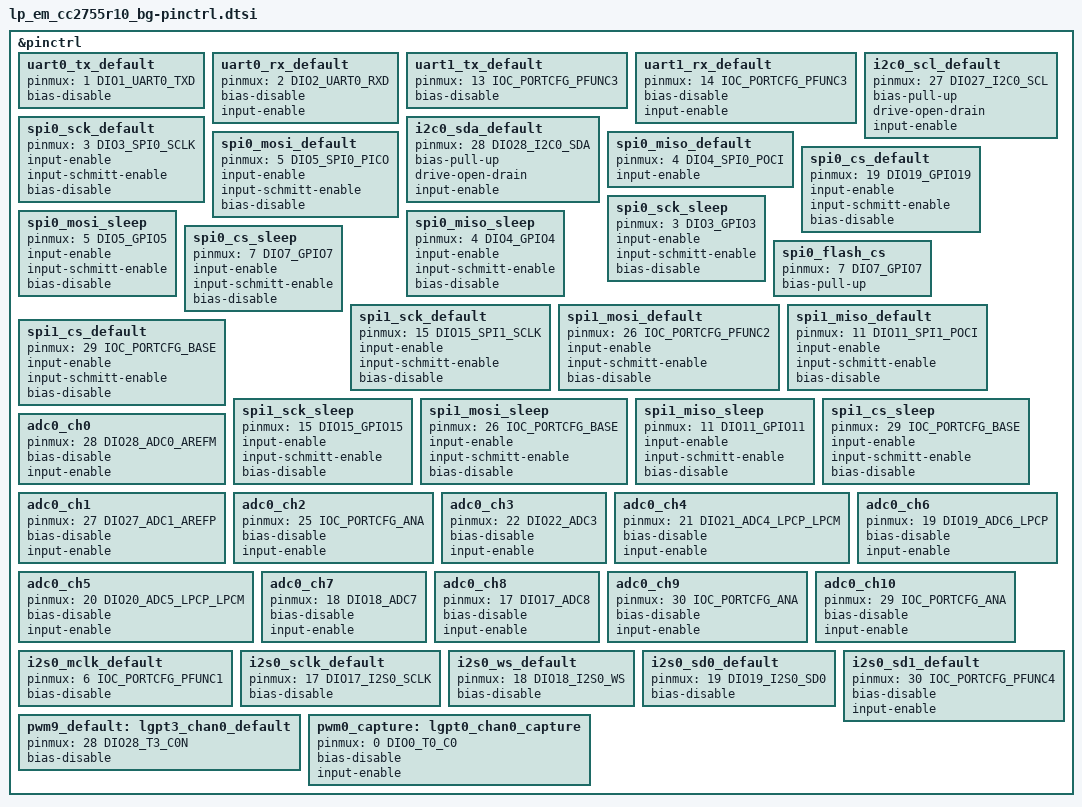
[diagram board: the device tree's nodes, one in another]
/*
 * Copyright (c) 2026 Texas Instruments Incorporated
 * Copyright (c) 2024 BayLibre, SAS
 *
 * SPDX-License-Identifier: Apache-2.0
 */

#include <zephyr/dt-bindings/pinctrl/cc27xx-pinctrl.h>

&pinctrl {
	/* UART0 */
	uart0_tx_default: uart0_tx_default {
		pinmux = <1 DIO1_UART0_TXD>;
		bias-disable;
	};

	uart0_rx_default: uart0_rx_default {
		pinmux = <2 DIO2_UART0_RXD>;
		bias-disable;
		input-enable;
	};

	/* UART1: DIO13 TXD, DIO14 RXD (mode 3) */
	uart1_tx_default: uart1_tx_default {
		pinmux = <13 IOC_PORTCFG_PFUNC3>;
		bias-disable;
	};

	uart1_rx_default: uart1_rx_default {
		pinmux = <14 IOC_PORTCFG_PFUNC3>;
		bias-disable;
		input-enable;
	};

	/* I2C0 */
	i2c0_scl_default: i2c0_scl_default {
		pinmux = <27 DIO27_I2C0_SCL>;
		bias-pull-up;
		drive-open-drain;
		input-enable;
	};

	i2c0_sda_default: i2c0_sda_default {
		pinmux = <28 DIO28_I2C0_SDA>;
		bias-pull-up;
		drive-open-drain;
		input-enable;
	};

	/* SPI0 */
	spi0_sck_default: spi0_sck_default {
		pinmux = <3 DIO3_SPI0_SCLK>;
		input-enable;
		input-schmitt-enable;
		bias-disable;
	};

	spi0_mosi_default: spi0_mosi_default {
		pinmux = <5 DIO5_SPI0_PICO>;
		input-enable;
		input-schmitt-enable;
		bias-disable;
	};

	spi0_miso_default: spi0_miso_default {
		pinmux = <4 DIO4_SPI0_POCI>;
		input-enable;
	};

	spi0_cs_default: spi0_cs_default {
		pinmux = <19 DIO19_GPIO19>;
		input-enable;
		input-schmitt-enable;
		bias-disable;
	};

	spi0_sck_sleep: spi0_sck_sleep {
		pinmux = <3 DIO3_GPIO3>;
		input-enable;
		input-schmitt-enable;
		bias-disable;
	};

	spi0_mosi_sleep: spi0_mosi_sleep {
		pinmux = <5 DIO5_GPIO5>;
		input-enable;
		input-schmitt-enable;
		bias-disable;
	};

	spi0_miso_sleep: spi0_miso_sleep {
		pinmux = <4 DIO4_GPIO4>;
		input-enable;
		input-schmitt-enable;
		bias-disable;
	};

	spi0_cs_sleep: spi0_cs_sleep {
		pinmux = <7 DIO7_GPIO7>;
		input-enable;
		input-schmitt-enable;
		bias-disable;
	};

	spi0_flash_cs: spi0_flash_cs {
		pinmux = <7 DIO7_GPIO7>;
		bias-pull-up;
	};

	/* SPI1: DIO15 SCLK, DIO26 PICO, DIO11 POCI, DIO29 CS (GPIO) */
	spi1_sck_default: spi1_sck_default {
		pinmux = <15 DIO15_SPI1_SCLK>;
		input-enable;
		input-schmitt-enable;
		bias-disable;
	};

	spi1_mosi_default: spi1_mosi_default {
		pinmux = <26 IOC_PORTCFG_PFUNC2>;
		input-enable;
		input-schmitt-enable;
		bias-disable;
	};

	spi1_miso_default: spi1_miso_default {
		pinmux = <11 DIO11_SPI1_POCI>;
		input-enable;
		input-schmitt-enable;
		bias-disable;
	};

	spi1_cs_default: spi1_cs_default {
		pinmux = <29 IOC_PORTCFG_BASE>;
		input-enable;
		input-schmitt-enable;
		bias-disable;
	};

	spi1_sck_sleep: spi1_sck_sleep {
		pinmux = <15 DIO15_GPIO15>;
		input-enable;
		input-schmitt-enable;
		bias-disable;
	};

	spi1_mosi_sleep: spi1_mosi_sleep {
		pinmux = <26 IOC_PORTCFG_BASE>;
		input-enable;
		input-schmitt-enable;
		bias-disable;
	};

	spi1_miso_sleep: spi1_miso_sleep {
		pinmux = <11 DIO11_GPIO11>;
		input-enable;
		input-schmitt-enable;
		bias-disable;
	};

	spi1_cs_sleep: spi1_cs_sleep {
		pinmux = <29 IOC_PORTCFG_BASE>;
		input-enable;
		input-schmitt-enable;
		bias-disable;
	};

	/* ADC channels.
	 *
	 * Some pins are shared with other options and must not be selected
	 * together: ch5 (DIO20) with Button 1, ch6/7/8 (DIO19/18/17) with I2S0,
	 * ch9 (DIO30) with I2S0 SD1, ch10 (DIO29) with the SPI1 CS, and ch0/ch1
	 * (DIO28/27) with I2C0.
	 */

	adc0_ch0: adc0_ch0 {
		pinmux = <28 DIO28_ADC0_AREFM>;
		bias-disable;
		input-enable;
	};

	adc0_ch1: adc0_ch1 {
		pinmux = <27 DIO27_ADC1_AREFP>;
		bias-disable;
		input-enable;
	};

	adc0_ch2: adc0_ch2 {
		pinmux = <25 IOC_PORTCFG_ANA>;
		bias-disable;
		input-enable;
	};

	adc0_ch3: adc0_ch3 {
		pinmux = <22 DIO22_ADC3>;
		bias-disable;
		input-enable;
	};

	adc0_ch4: adc0_ch4 {
		pinmux = <21 DIO21_ADC4_LPCP_LPCM>;
		bias-disable;
		input-enable;
	};

	adc0_ch5: adc0_ch5 {
		pinmux = <20 DIO20_ADC5_LPCP_LPCM>;
		bias-disable;
		input-enable;
	};

	adc0_ch6: adc0_ch6 {
		pinmux = <19 DIO19_ADC6_LPCP>;
		bias-disable;
		input-enable;
	};

	adc0_ch7: adc0_ch7 {
		pinmux = <18 DIO18_ADC7>;
		bias-disable;
		input-enable;
	};

	adc0_ch8: adc0_ch8 {
		pinmux = <17 DIO17_ADC8>;
		bias-disable;
		input-enable;
	};

	adc0_ch9: adc0_ch9 {
		pinmux = <30 IOC_PORTCFG_ANA>;
		bias-disable;
		input-enable;
	};

	adc0_ch10: adc0_ch10 {
		pinmux = <29 IOC_PORTCFG_ANA>;
		bias-disable;
		input-enable;
	};

	/* I2S0 shares DIO17/18/19 with ADC ch8/7/6 and DIO30 with ADC ch9.
	 * DIO6=MCLK, DIO17=SCLK, DIO18=WS, DIO19=SD0(TX), DIO30=SD1(RX)
	 */
	i2s0_mclk_default: i2s0_mclk_default {
		pinmux = <6 IOC_PORTCFG_PFUNC1>;
		bias-disable;
	};

	i2s0_sclk_default: i2s0_sclk_default {
		pinmux = <17 DIO17_I2S0_SCLK>;
		bias-disable;
	};

	i2s0_ws_default: i2s0_ws_default {
		pinmux = <18 DIO18_I2S0_WS>;
		bias-disable;
	};

	i2s0_sd0_default: i2s0_sd0_default {
		pinmux = <19 DIO19_I2S0_SD0>;
		bias-disable;
	};

	i2s0_sd1_default: i2s0_sd1_default {
		pinmux = <30 IOC_PORTCFG_PFUNC4>;
		bias-disable;
		input-enable;
	};

	/* LGPT3 ch0 output (DIO28, T3_C0N) */
	pwm9_default: lgpt3_chan0_default {
		pinmux = <28 DIO28_T3_C0N>;
		bias-disable;
	};

	/* LGPT0 ch0 capture input (DIO0, T0_C0) */
	pwm0_capture: lgpt0_chan0_capture {
		pinmux = <0 DIO0_T0_C0>;
		bias-disable;
		input-enable;
	};
};
